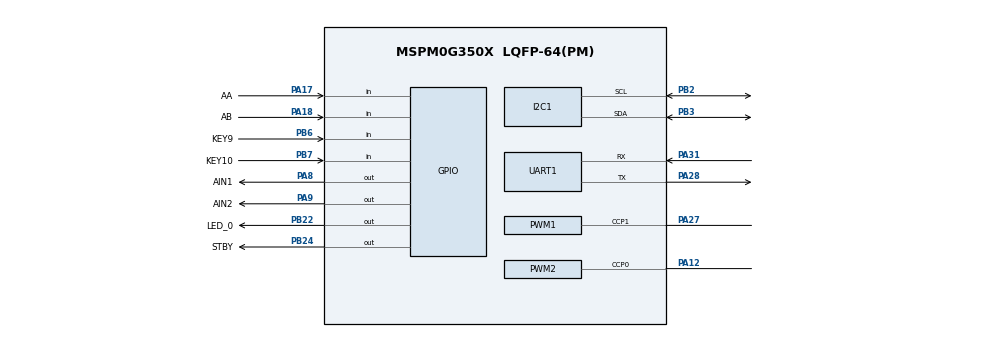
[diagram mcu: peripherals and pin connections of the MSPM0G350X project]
/**
 * @cliArgs --device "MSPM0G350X" --part "Default" --package "LQFP-64(PM)" --product "mspm0_sdk@2.11.00.07"
 * @versions {"tool":"1.26.2+4477"}
 */

/**
 * Import the modules used in this configuration.
 */
const GPIO   = scripting.addModule("/ti/driverlib/GPIO", {}, false);
const GPIO1  = GPIO.addInstance();
const GPIO2  = GPIO.addInstance();
const GPIO3  = GPIO.addInstance();
const I2C    = scripting.addModule("/ti/driverlib/I2C", {}, false);
const I2C1   = I2C.addInstance();
const PWM    = scripting.addModule("/ti/driverlib/PWM", {}, false);
const PWM1   = PWM.addInstance();
const PWM2   = PWM.addInstance();
const SYSCTL = scripting.addModule("/ti/driverlib/SYSCTL");
const TIMER  = scripting.addModule("/ti/driverlib/TIMER", {}, false);
const TIMER1 = TIMER.addInstance();
const UART   = scripting.addModule("/ti/driverlib/UART", {}, false);
const UART1  = UART.addInstance();

/**
 * Write custom configuration values to the imported modules.
 */
const divider9       = system.clockTree["UDIV"];
divider9.divideValue = 2;

const multiplier2         = system.clockTree["PLL_QDIV"];
multiplier2.multiplyValue = 4;

const mux4       = system.clockTree["EXHFMUX"];
mux4.inputSelect = "EXHFMUX_XTAL";

const mux8       = system.clockTree["HSCLKMUX"];
mux8.inputSelect = "HSCLKMUX_SYSPLL0";

const mux12       = system.clockTree["SYSPLLMUX"];
mux12.inputSelect = "zSYSPLLMUX_HFCLK";

const pinFunction4     = system.clockTree["HFXT"];
pinFunction4.inputFreq = 40;
pinFunction4.enable    = true;

GPIO1.$name                         = "LED";
GPIO1.associatedPins[0].$name       = "LED_0";
GPIO1.associatedPins[0].pin.$assign = "PB22";

const Board = scripting.addModule("/ti/driverlib/Board", {}, false);

GPIO2.$name                              = "KEY";
GPIO2.associatedPins.create(2);
GPIO2.associatedPins[0].$name            = "KEY9";
GPIO2.associatedPins[0].direction        = "INPUT";
GPIO2.associatedPins[0].internalResistor = "PULL_DOWN";
GPIO2.associatedPins[0].interruptEn      = true;
GPIO2.associatedPins[0].polarity         = "RISE";
GPIO2.associatedPins[0].pin.$assign      = "PB6";
GPIO2.associatedPins[1].$name            = "KEY10";
GPIO2.associatedPins[1].direction        = "INPUT";
GPIO2.associatedPins[1].internalResistor = "PULL_DOWN";
GPIO2.associatedPins[1].interruptEn      = true;
GPIO2.associatedPins[1].polarity         = "RISE";
GPIO2.associatedPins[1].pin.$assign      = "PB7";

GPIO3.$name                              = "DC_MOTOR";
GPIO3.associatedPins.create(5);
GPIO3.associatedPins[0].$name            = "AIN1";
GPIO3.associatedPins[0].pin.$assign      = "PA8";
GPIO3.associatedPins[1].$name            = "AIN2";
GPIO3.associatedPins[1].pin.$assign      = "PA9";
GPIO3.associatedPins[2].$name            = "STBY";
GPIO3.associatedPins[2].pin.$assign      = "PB24";
GPIO3.associatedPins[3].$name            = "AA";
GPIO3.associatedPins[3].direction        = "INPUT";
GPIO3.associatedPins[3].interruptEn      = true;
GPIO3.associatedPins[3].polarity         = "RISE";
GPIO3.associatedPins[3].internalResistor = "PULL_DOWN";
GPIO3.associatedPins[3].pin.$assign      = "PA17";
GPIO3.associatedPins[4].$name            = "AB";
GPIO3.associatedPins[4].direction        = "INPUT";
GPIO3.associatedPins[4].internalResistor = "PULL_DOWN";
GPIO3.associatedPins[4].pin.$assign      = "PA18";

I2C1.$name                             = "OLED";
I2C1.basicEnableController             = true;
I2C1.advDigitalGlitchFilter            = "CLOCKS_1";
I2C1.advControllerRXFIFOTRIG           = "BYTES_8";
I2C1.advControllerTXFIFOTRIG           = "BYTES_7";
I2C1.enableDMAEvent1                   = false;
I2C1.enableDMAEvent2                   = false;
I2C1.peripheral.$assign                = "I2C1";
I2C1.peripheral.sdaPin.$assign         = "PB3";
I2C1.peripheral.sclPin.$assign         = "PB2";
I2C1.sdaPinConfig.$name                = "ti_driverlib_gpio_GPIOPinGeneric0";
I2C1.sdaPinConfig.hideOutputInversion  = scripting.forceWrite(false);
I2C1.sdaPinConfig.onlyInternalResistor = scripting.forceWrite(false);
I2C1.sdaPinConfig.passedPeripheralType = scripting.forceWrite("Digital");
I2C1.sdaPinConfig.enableConfig         = true;
I2C1.sdaPinConfig.internalResistor     = "PULL_UP";
I2C1.sclPinConfig.$name                = "ti_driverlib_gpio_GPIOPinGeneric1";
I2C1.sclPinConfig.hideOutputInversion  = scripting.forceWrite(false);
I2C1.sclPinConfig.onlyInternalResistor = scripting.forceWrite(false);
I2C1.sclPinConfig.passedPeripheralType = scripting.forceWrite("Digital");
I2C1.sclPinConfig.enableConfig         = true;
I2C1.sclPinConfig.internalResistor     = "PULL_UP";

PWM1.$name                              = "SERVO";
PWM1.clockDivider                       = 8;
PWM1.clockPrescale                      = 100;
PWM1.pwmMode                            = "EDGE_ALIGN_UP";
PWM1.ccIndex                            = [1];
PWM1.timerCount                         = 2000;
PWM1.timerStartTimer                    = true;
PWM1.ccp1PinConfig.direction            = scripting.forceWrite("OUTPUT");
PWM1.ccp1PinConfig.hideOutputInversion  = scripting.forceWrite(false);
PWM1.ccp1PinConfig.onlyInternalResistor = scripting.forceWrite(false);
PWM1.ccp1PinConfig.passedPeripheralType = scripting.forceWrite("Digital");
PWM1.ccp1PinConfig.$name                = "ti_driverlib_gpio_GPIOPinGeneric5";
PWM1.peripheral.$assign                 = "TIMG7";
PWM1.peripheral.ccp1Pin.$assign         = "PA27";
PWM1.PWM_CHANNEL_1.$name                = "ti_driverlib_pwm_PWMTimerCC0";
PWM1.PWM_CHANNEL_1.ccValue              = 150;

PWM2.$name                              = "PWMA";
PWM2.ccIndex                            = [0];
PWM2.timerCount                         = 4000;
PWM2.timerStartTimer                    = true;
PWM2.pwmMode                            = "EDGE_ALIGN_UP";
PWM2.PWM_CHANNEL_0.$name                = "ti_driverlib_pwm_PWMTimerCC1";
PWM2.ccp0PinConfig.$name                = "ti_driverlib_gpio_GPIOPinGeneric4";
PWM2.ccp0PinConfig.direction            = scripting.forceWrite("OUTPUT");
PWM2.ccp0PinConfig.hideOutputInversion  = scripting.forceWrite(false);
PWM2.ccp0PinConfig.onlyInternalResistor = scripting.forceWrite(false);
PWM2.ccp0PinConfig.passedPeripheralType = scripting.forceWrite("Digital");
PWM2.peripheral.$assign                 = "TIMG0";
PWM2.peripheral.ccp0Pin.$assign         = "PA12";

SYSCTL.forceDefaultClkConfig = true;
SYSCTL.clockTreeEn           = true;

TIMER1.$name              = "MOTOR_PID";
TIMER1.timerMode          = "PERIODIC_UP";
TIMER1.timerPeriod        = "50 ms";
TIMER1.timerClkPrescale   = 100;
TIMER1.interrupts         = ["LOAD"];
TIMER1.peripheral.$assign = "TIMA0";

UART1.$name                            = "PRINT";
UART1.targetBaudRate                   = 115200;
UART1.enabledInterrupts                = ["RX"];
UART1.peripheral.rxPin.$assign         = "PA31";
UART1.peripheral.txPin.$assign         = "PA28";
UART1.txPinConfig.direction            = scripting.forceWrite("OUTPUT");
UART1.txPinConfig.hideOutputInversion  = scripting.forceWrite(false);
UART1.txPinConfig.onlyInternalResistor = scripting.forceWrite(false);
UART1.txPinConfig.passedPeripheralType = scripting.forceWrite("Digital");
UART1.txPinConfig.$name                = "ti_driverlib_gpio_GPIOPinGeneric2";
UART1.rxPinConfig.hideOutputInversion  = scripting.forceWrite(false);
UART1.rxPinConfig.onlyInternalResistor = scripting.forceWrite(false);
UART1.rxPinConfig.passedPeripheralType = scripting.forceWrite("Digital");
UART1.rxPinConfig.$name                = "ti_driverlib_gpio_GPIOPinGeneric3";

/**
 * Pinmux solution for unlocked pins/peripherals. This ensures that minor changes to the automatic solver in a future
 * version of the tool will not impact the pinmux you originally saw.  These lines can be completely deleted in order to
 * re-solve from scratch.
 */
pinFunction4.peripheral.$suggestSolution           = "SYSCTL";
pinFunction4.peripheral.hfxInPin.$suggestSolution  = "PA5";
pinFunction4.peripheral.hfxOutPin.$suggestSolution = "PA6";
Board.peripheral.$suggestSolution                  = "DEBUGSS";
Board.peripheral.swclkPin.$suggestSolution         = "PA20";
Board.peripheral.swdioPin.$suggestSolution         = "PA19";
UART1.peripheral.$suggestSolution                  = "UART0";
